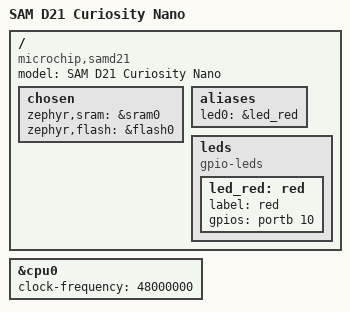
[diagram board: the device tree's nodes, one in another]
/dts-v1/;

#include <atmel/samd21.dtsi>
#include <atmel/samx2xx17.dtsi>

/{
    model = "SAM D21 Curiosity Nano";
    compatible = "microchip,samd21";

    chosen {
		zephyr,sram = &sram0;
        zephyr,flash = &flash0;
	};

    aliases {
        led0 = &led_red;
    };


    leds {
		compatible = "gpio-leds";
		status = "okay";

		led_red: red {
			label = "red";
			gpios = <&portb 10 GPIO_ACTIVE_HIGH>;
		};
	};
};

&cpu0 {
	clock-frequency = <48000000>;
};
